# MPU_PRCM_DEVICE register map
Vendor: Texas Instruments
Peripheral module from a debugger description file (folder DRA75x_DRA74x).
Registers are 32-bit, access per field, reset 0x1 unless marked. A register's access mark holds for its fields unless they carry their own. Offsets are as the file gives them; lines under a group give offsets from that group; [hi:lo] are bit positions; {n}, {i} and the like mark numbered series; 'fields as' and 'values as' point back to an identical list; <NAME> marks a mode.

## MPU_PRCM_DEVICE
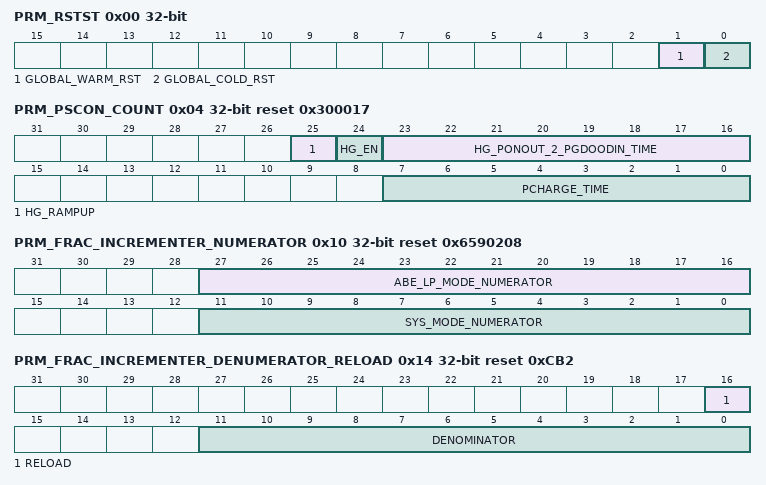
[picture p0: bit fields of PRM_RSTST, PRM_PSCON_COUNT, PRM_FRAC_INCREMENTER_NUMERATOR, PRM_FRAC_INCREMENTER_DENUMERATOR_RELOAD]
0x00 PRM_RSTST access not given — This register logs the global reset sources, thus contains information regarding the cold/warm reset events generated by global PRCM. Each bit is set upon release of the domain reset signal. Must be cleared by software. This register is insensitive to global warm reset.
  [1] GLOBAL_WARM_RST — Global warm reset event generated by global PRCM (access RW (W1toClr))
    0=No global warm reset; 1=Global external warm reset has occurred
  [0] GLOBAL_COLD_RST — Power-on (cold) reset event generated by global PRCM (access RW (W1toClr))
    0=No power-on reset; 1=Power-on reset has occurred
0x04 PRM_PSCON_COUNT reset 0x300017 — Programmable precharge count for L1cache
  [25] HG_RAMPUP rw — Ramp-up mode selection of HG power chain switch
    0=SLOW (Slow ramp-up mode – HG weak chain is used. The delay between PONOUTHG and PGOODINHG is defined by the HG_PONOUT_2_PGDOODIN_TIME bit field.); 1=FAST (Fast ramp-up mode – HG weak chain is not used)
  [24] HG_EN rw — HG power chain switch enable
    0=HG_DISABLE (HG power chain switch is disabled); 1=HG_ENABLE (HG power chain switch is enabled)
  [23:16] HG_PONOUT_2_PGDOODIN_TIME rw — The value set in this field determines the slow ramp-up time and the duration (number of cycles) of the PONOUTHG to PGOODINHG (transition for power domain without DPS). The duration is computed as 8 x HG_PONOUT_2_PGDOODIN_TIME of system clock cycles. Target is 10us.
  [7:0] PCHARGE_TIME rw — Programmable precharge count during retention
0x10 PRM_FRAC_INCREMENTER_NUMERATOR reset 0x6590208 — Fractional incrementor
  [27:16] ABE_LP_MODE_NUMERATOR rw — Numerator to be used in fractional incrementor when ABE_LP_CLK clock is used as PRCM clock. Reset value corresponds to ABE_LP_CLK clock = 12.288 MHz.
  [11:0] SYS_MODE_NUMERATOR rw — Numerator to be used in fractional incrementor when SYS_CLK1 is used as PRCM clock.NOTE: The reset value corresponds to SYS_CLK1 = 38.4 MHz. Because the device does not support such SYS_CLK1 frequency, it is SW responsibility to set a value corresponding to one of the SYS_CLK1 frequencies listed in . .
0x14 PRM_FRAC_INCREMENTER_DENUMERATOR_RELOAD reset 0xCB2 — Reload command and denominator to be used in fractional incrementor
  [16] RELOAD rw — Reload counter value from coarse counter. 0-&gt;1 transition in this field is used to load the coarse counter into counter.
  [11:0] DENOMINATOR rw — Denominator to be used in fractional incrementor when when SYS_CLK1 is used as PRCM clock.NOTE: The reset value corresponds to SYS_CLK1 = 38.4 MHz. Because the device does not support such SYS_CLK1 frequency, it is SW responsibility to set a value corresponding to one of the SYS_CLK1 frequencies listed in . .
